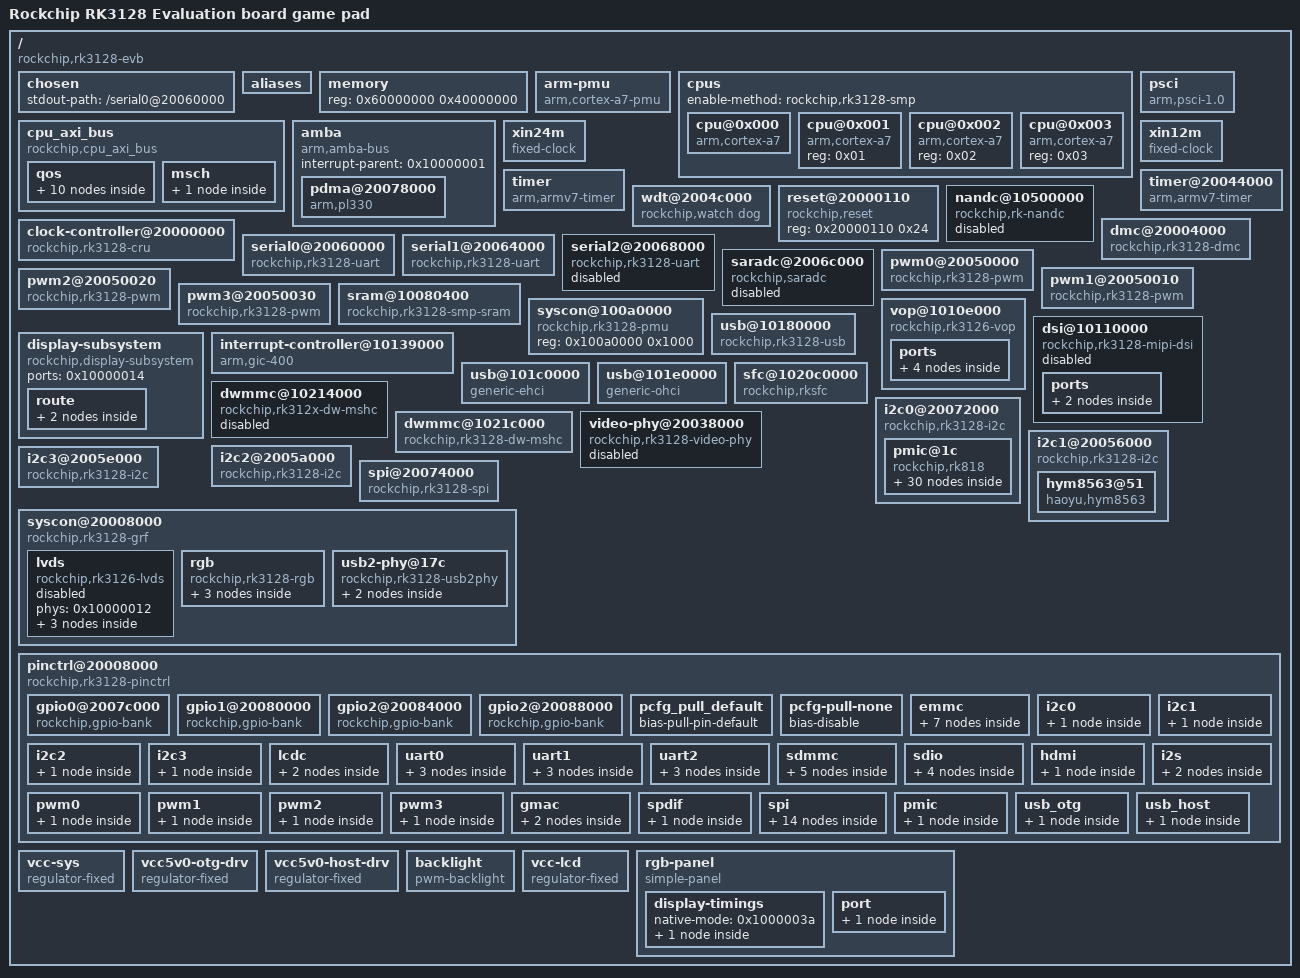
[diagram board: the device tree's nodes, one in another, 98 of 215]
/dts-v1/;

/ {
	#address-cells = <0x01>;
	#size-cells = <0x01>;
	compatible = "rockchip,rk3128-evb\0rockchip,rk3128";
	rockchip,sram = <0x10000000>;
	interrupt-parent = <0x10000001>;
	model = "Rockchip RK3128 Evaluation board game pad";

	chosen {
		stdout-path = "/serial0@20060000";
	};

	aliases {
		gpio0 = "/pinctrl@20008000/gpio0@2007c000";
		gpio1 = "/pinctrl@20008000/gpio1@20080000";
		gpio2 = "/pinctrl@20008000/gpio2@20084000";
		gpio3 = "/pinctrl@20008000/gpio2@20088000";
		i2c0 = "/i2c0@20072000";
		i2c1 = "/i2c1@20056000";
		i2c2 = "/i2c2@2005a000";
		i2c3 = "/i2c3@2005e000";
		spi0 = "/spi@20074000";
		serial0 = "/serial0@20060000";
		serial1 = "/serial1@20064000";
		serial2 = "/serial2@20068000";
		mmc0 = "/dwmmc@1021c000";
		mmc1 = "/dwmmc@10214000";
	};

	memory {
		device_type = "memory";
		reg = <0x60000000 0x40000000>;
	};

	arm-pmu {
		compatible = "arm,cortex-a7-pmu";
		interrupts = <0x00 0x4c 0x04 0x00 0x4d 0x04 0x00 0x4e 0x04 0x00 0x4f 0x04>;
	};

	cpus {
		#address-cells = <0x01>;
		#size-cells = <0x00>;
		enable-method = "rockchip,rk3128-smp";

		cpu@0x000 {
			device_type = "cpu";
			compatible = "arm,cortex-a7";
			reg = <0x00>;
			operating-points = <0xc7380 0xf4240>;
			#cooling-cells = <0x02>;
			clock-latency = <0x9c40>;
			clocks = <0x10000002 0x05>;
		};

		cpu@0x001 {
			device_type = "cpu";
			compatible = "arm,cortex-a7";
			reg = <0x01>;
		};

		cpu@0x002 {
			device_type = "cpu";
			compatible = "arm,cortex-a7";
			reg = <0x02>;
		};

		cpu@0x003 {
			device_type = "cpu";
			compatible = "arm,cortex-a7";
			reg = <0x03>;
		};
	};

	cpu_axi_bus {
		compatible = "rockchip,cpu_axi_bus";
		#address-cells = <0x01>;
		#size-cells = <0x01>;
		ranges;

		qos {
			#address-cells = <0x01>;
			#size-cells = <0x01>;
			ranges;

			crypto {
				reg = <0x10128080 0x20>;
			};

			core {
				reg = <0x1012a000 0x20>;
			};

			peri {
				reg = <0x1012c000 0x20>;
			};

			gpu {
				reg = <0x1012d000 0x20>;
			};

			vpu {
				reg = <0x1012e000 0x20>;
			};

			rga {
				reg = <0x1012f000 0x20>;
			};

			ebc {
				reg = <0x1012f080 0x20>;
			};

			iep {
				reg = <0x1012f100 0x20>;
			};

			lcdc {
				reg = <0x1012f180 0x20>;
				rockchip,priority = <0x03 0x03>;
			};

			vip {
				reg = <0x1012f200 0x20>;
				rockchip,priority = <0x03 0x03>;
			};
		};

		msch {
			#address-cells = <0x01>;
			#size-cells = <0x01>;
			ranges;

			msch@10128000 {
				reg = <0x10128000 0x20>;
				rockchip,read-latency = <0x3f>;
			};
		};
	};

	psci {
		compatible = "arm,psci-1.0";
		method = "smc";
		u-boot,dm-pre-reloc;
		status = "okay";
	};

	amba {
		compatible = "arm,amba-bus";
		#address-cells = <0x01>;
		#size-cells = <0x01>;
		interrupt-parent = <0x10000001>;
		ranges;

		pdma@20078000 {
			compatible = "arm,pl330\0arm,primecell";
			reg = <0x20078000 0x4000>;
			arm,pl330-broken-no-flushp;
			interrupts = <0x00 0x00 0x04 0x00 0x01 0x04>;
			#dma-cells = <0x01>;
			clocks = <0x10000002 0xc2>;
			clock-names = "apb_pclk";
			phandle = <0x10000008>;
		};
	};

	xin24m {
		compatible = "fixed-clock";
		clock-frequency = <0x16e3600>;
		clock-output-names = "xin24m";
		#clock-cells = <0x00>;
		phandle = <0x10000003>;
	};

	xin12m {
		compatible = "fixed-clock";
		clocks = <0x10000003>;
		clock-frequency = <0xb71b00>;
		clock-output-names = "xin12m";
		#clock-cells = <0x00>;
	};

	timer {
		compatible = "arm,armv7-timer";
		arm,cpu-registers-not-fw-configured;
		interrupts = <0x01 0x0d 0xf04 0x01 0x0e 0xf04>;
		clock-frequency = <0x16e3600>;
	};

	timer@20044000 {
		compatible = "arm,armv7-timer";
		reg = <0x20044000 0xb8>;
		interrupts = <0x00 0x1c 0x04>;
		rockchip,broadcast = <0x01>;
	};

	wdt@2004c000 {
		compatible = "rockchip,watch dog";
		reg = <0x2004c000 0x100>;
		clock-names = "pclk_wdt";
		interrupts = <0x00 0x22 0x04>;
		rockchip,irq = <0x01>;
		rockchip,timeout = <0x3c>;
		rockchip,atboot = <0x01>;
		rockchip,debug = <0x00>;
	};

	reset@20000110 {
		compatible = "rockchip,reset";
		reg = <0x20000110 0x24>;
		#reset-cells = <0x01>;
	};

	nandc@10500000 {
		compatible = "rockchip,rk-nandc";
		reg = <0x10500000 0x4000>;
		interrupts = <0x00 0x12 0x04>;
		nandc_id = <0x00>;
		clocks = <0x10000002 0x43 0x10000002 0x1c5>;
		clock-names = "clk_nandc\0hclk_nandc";
		status = "disabled";
	};

	dmc@20004000 {
		compatible = "rockchip,rk3128-dmc\0syscon";
		reg = <0x00 0x20004000 0x00 0x1000>;
		u-boot,dm-pre-reloc;
	};

	clock-controller@20000000 {
		compatible = "rockchip,rk3128-cru";
		reg = <0x20000000 0x1000>;
		rockchip,grf = <0x10000004>;
		#clock-cells = <0x01>;
		#reset-cells = <0x01>;
		assigned-clocks = <0x10000002 0x04>;
		assigned-clock-rates = <0x2367b880>;
		u-boot,dm-pre-reloc;
		phandle = <0x10000002>;
	};

	serial0@20060000 {
		compatible = "rockchip,rk3128-uart\0snps,dw-apb-uart";
		reg = <0x20060000 0x100>;
		interrupts = <0x00 0x14 0x04>;
		reg-shift = <0x02>;
		reg-io-width = <0x04>;
		clock-frequency = <0x16e3600>;
		clocks = <0x10000002 0x4d 0x10000002 0x155>;
		clock-names = "baudclk\0apb_pclk";
		pinctrl-names = "default";
		pinctrl-0 = <0x10000005 0x10000006 0x10000007>;
		dmas = <0x10000008 0x02 0x10000008 0x03>;
		#dma-cells = <0x02>;
		u-boot,dm-pre-reloc;
		status = "okay";
	};

	serial1@20064000 {
		compatible = "rockchip,rk3128-uart\0snps,dw-apb-uart";
		reg = <0x20064000 0x100>;
		interrupts = <0x00 0x15 0x04>;
		reg-shift = <0x02>;
		reg-io-width = <0x04>;
		clock-frequency = <0x16e3600>;
		clocks = <0x10000002 0x4e 0x10000002 0x156>;
		clock-names = "baudclk\0apb_pclk";
		pinctrl-names = "default";
		pinctrl-0 = <0x10000009>;
		dmas = <0x10000008 0x04 0x10000008 0x05>;
		#dma-cells = <0x02>;
	};

	serial2@20068000 {
		compatible = "rockchip,rk3128-uart\0snps,dw-apb-uart";
		reg = <0x20068000 0x100>;
		interrupts = <0x00 0x16 0x04>;
		reg-shift = <0x02>;
		reg-io-width = <0x04>;
		clock-frequency = <0x16e3600>;
		clocks = <0x10000002 0x4f 0x10000002 0x157>;
		clock-names = "baudclk\0apb_pclk";
		pinctrl-names = "default";
		pinctrl-0 = <0x1000000a>;
		dmas = <0x10000008 0x06 0x10000008 0x07>;
		#dma-cells = <0x02>;
		status = "disabled";
	};

	saradc@2006c000 {
		compatible = "rockchip,saradc";
		reg = <0x2006c000 0x100>;
		interrupts = <0x00 0x11 0x04>;
		#io-channel-cells = <0x01>;
		clocks = <0x10000002 0x5b 0x10000002 0x13e>;
		clock-names = "saradc\0apb_pclk";
		resets = <0x10000002 0x57>;
		reset-names = "saradc-apb";
		status = "disabled";
	};

	pwm0@20050000 {
		compatible = "rockchip,rk3128-pwm\0rockchip,rk3288-pwm";
		reg = <0x20050000 0x10>;
		#pwm-cells = <0x03>;
		pinctrl-names = "active";
		pinctrl-0 = <0x1000000b>;
		clocks = <0x10000002 0x15e>;
		clock-names = "pwm";
		phandle = <0x10000036>;
	};

	pwm1@20050010 {
		compatible = "rockchip,rk3128-pwm\0rockchip,rk3288-pwm";
		reg = <0x20050010 0x10>;
		#pwm-cells = <0x02>;
		pinctrl-names = "active";
		pinctrl-0 = <0x1000000c>;
		clocks = <0x10000002 0x15e>;
		clock-names = "pwm";
	};

	pwm2@20050020 {
		compatible = "rockchip,rk3128-pwm\0rockchip,rk3288-pwm";
		reg = <0x20050020 0x10>;
		#pwm-cells = <0x02>;
		pinctrl-names = "active";
		pinctrl-0 = <0x1000000d>;
		clocks = <0x10000002 0x15e>;
		clock-names = "pwm";
	};

	pwm3@20050030 {
		compatible = "rockchip,rk3128-pwm\0rockchip,rk3288-pwm";
		reg = <0x20050030 0x10>;
		#pwm-cells = <0x02>;
		pinctrl-names = "active";
		pinctrl-0 = <0x1000000e>;
		clocks = <0x10000002 0x15e>;
		clock-names = "pwm";
	};

	sram@10080400 {
		compatible = "rockchip,rk3128-smp-sram\0mmio-sram";
		reg = <0x10080400 0x1c00>;
		map-exec;
		map-cacheable;
		phandle = <0x10000000>;
	};

	syscon@100a0000 {
		compatible = "rockchip,rk3128-pmu\0syscon\0simple-mfd";
		reg = <0x100a0000 0x1000>;
		#address-cells = <0x01>;
		#size-cells = <0x01>;
	};

	vop@1010e000 {
		compatible = "rockchip,rk3126-vop";
		reg = <0x1010e000 0x100 0x1010ec00 0x400>;
		reg-names = "regs\0gamma_lut";
		interrupts = <0x00 0x09 0x04>;
		clocks = <0x10000002 0xcc 0x10000002 0xbe 0x10000002 0x1cf>;
		clock-names = "aclk_vop\0dclk_vop\0hclk_vop";
		status = "okay";

		ports {

			port {
				#address-cells = <0x01>;
				#size-cells = <0x00>;
				phandle = <0x10000014>;

				endpoint@0 {
					reg = <0x00>;
					remote-endpoint = <0x1000000f>;
					phandle = <0x10000015>;
				};

				endpoint@1 {
					reg = <0x01>;
					remote-endpoint = <0x10000010>;
					phandle = <0x10000013>;
				};

				endpoint@2 {
					reg = <0x02>;
					remote-endpoint = <0x10000011>;
					phandle = <0x1000002e>;
				};
			};
		};
	};

	dsi@10110000 {
		compatible = "rockchip,rk3128-mipi-dsi";
		reg = <0x10110000 0x4000>;
		interrupts = <0x00 0x21 0x04>;
		clocks = <0x10000002 0x145 0x10000002 0x1d5 0x10000012>;
		clock-names = "pclk\0h2p\0hs_clk";
		resets = <0x10000002 0x89>;
		reset-names = "apb";
		phys = <0x10000012>;
		phy-names = "mipi_dphy";
		rockchip,grf = <0x10000004>;
		#address-cells = <0x01>;
		#size-cells = <0x00>;
		status = "disabled";

		ports {

			port {

				endpoint {
					remote-endpoint = <0x10000013>;
					phandle = <0x10000010>;
				};
			};
		};
	};

	display-subsystem {
		compatible = "rockchip,display-subsystem";
		ports = <0x10000014>;
		status = "okay";

		route {

			route-lvds {
				logo,uboot = "logo.bmp";
				logo,kernel = "logo_kernel.bmp";
				logo,mode = "fullscreen";
				charge_logo,mode = "center";
				connect = <0x10000015>;
				status = "okay";
			};

			route-dsi {
				logo,uboot = "logo.bmp";
				logo,kernel = "logo_kernel.bmp";
				logo,mode = "fullscreen";
				charge_logo,mode = "center";
				connect = <0x10000013>;
				status = "disabled";
			};
		};
	};

	interrupt-controller@10139000 {
		compatible = "arm,gic-400";
		interrupt-controller;
		#interrupt-cells = <0x03>;
		#address-cells = <0x00>;
		reg = <0x10139000 0x1000 0x1013a000 0x1000 0x1013c000 0x2000 0x1013e000 0x2000>;
		interrupts = <0x01 0x09 0xf04>;
		phandle = <0x10000001>;
	};

	usb@10180000 {
		compatible = "rockchip,rk3128-usb\0rockchip,rk3288-usb\0snps,dwc2";
		reg = <0x10180000 0x40000>;
		interrupts = <0x00 0x0a 0x04>;
		dr_mode = "otg";
		g-use-dma;
		hnp-srp-disable;
		phys = <0x10000016>;
		phy-names = "usb";
		status = "okay";
		u-boot,dm-pre-reloc;
		vbus-supply = <0x10000017>;
	};

	usb@101c0000 {
		compatible = "generic-ehci";
		reg = <0x101c0000 0x20000>;
		interrupts = <0x00 0x0b 0x04>;
		phys = <0x10000018>;
		phy-names = "usb";
		status = "okay";
	};

	usb@101e0000 {
		compatible = "generic-ohci";
		reg = <0x101e0000 0x20000>;
		interrupts = <0x00 0x20 0x04>;
		phys = <0x10000018>;
		phy-names = "usb";
		status = "okay";
	};

	sfc@1020c0000 {
		compatible = "rockchip,rksfc";
		reg = <0x1020c000 0x4000>;
		#address-cells = <0x01>;
		#size-cells = <0x00>;
		interrupts = <0x00 0x09 0x04>;
		clocks = <0x10000002 0x99 0x10000002 0x1b7>;
		clock-names = "clk_sfc\0hclk_sfc";
		status = "okay";
		u-boot,dm-pre-reloc;
	};

	dwmmc@10214000 {
		compatible = "rockchip,rk312x-dw-mshc\0rockchip,rk3288-dw-mshc";
		reg = <0x10214000 0x4000>;
		max-frequency = <0x8f0d180>;
		interrupts = <0x00 0x0e 0x04>;
		clocks = <0x10000002 0x1c8 0x10000002 0x44 0x10000002 0x72 0x10000002 0x76>;
		clock-names = "biu\0ciu\0ciu-drv\0ciu-sample";
		fifo-depth = <0x100>;
		pinctrl-names = "default";
		pinctrl-0 = <0x10000019 0x1000001a 0x1000001b>;
		bus-width = <0x04>;
		status = "disabled";
	};

	dwmmc@1021c000 {
		compatible = "rockchip,rk3128-dw-mshc\0rockchip,rk3288-dw-mshc";
		reg = <0x1021c000 0x4000>;
		max-frequency = <0x8f0d180>;
		interrupts = <0x00 0x10 0x04>;
		clocks = <0x10000002 0x1cb 0x10000002 0x47 0x10000002 0x75 0x10000002 0x79>;
		clock-names = "biu\0ciu\0ciu-drv\0ciu-sample";
		bus-width = <0x08>;
		default-sample-phase = <0x9e>;
		num-slots = <0x01>;
		fifo-depth = <0x100>;
		pinctrl-names = "default";
		pinctrl-0 = <0x1000001c 0x1000001d 0x1000001e>;
		resets = <0x10000002 0x53>;
		reset-names = "reset";
		status = "okay";
		fifo-mode;
	};

	video-phy@20038000 {
		compatible = "rockchip,rk3128-video-phy";
		reg = <0x20038000 0x4000 0x10110000 0x4000>;
		clocks = <0x10000002 0x94 0x10000002 0x172 0x10000002 0x145>;
		clock-names = "ref\0pclk_phy\0pclk_host";
		#clock-cells = <0x00>;
		resets = <0x10000002 0x24>;
		reset-names = "rst";
		#phy-cells = <0x00>;
		status = "disabled";
		phandle = <0x10000012>;
	};

	i2c0@20072000 {
		compatible = "rockchip,rk3128-i2c\0rockchip,rk3288-i2c";
		reg = <0x20072000 0x1000>;
		interrupts = <0x00 0x18 0x04>;
		#address-cells = <0x01>;
		#size-cells = <0x00>;
		clock-names = "i2c";
		clocks = <0x10000002 0x14c>;
		pinctrl-names = "default";
		pinctrl-0 = <0x1000001f>;
		status = "okay";
		clock-frequency = <0x61a80>;

		pmic@1c {
			compatible = "rockchip,rk818";
			status = "okay";
			reg = <0x1c>;
			clock-output-names = "rk818-clkout1\0wifibt_32kin";
			interrupt-parent = <0x10000020>;
			interrupts = <0x16 0x08>;
			pinctrl-names = "default";
			pinctrl-0 = <0x10000021>;
			rockchip,system-power-controller;
			wakeup-source;
			#clock-cells = <0x01>;
			vcc1-supply = <0x10000022>;
			vcc2-supply = <0x10000022>;
			vcc3-supply = <0x10000022>;
			vcc4-supply = <0x10000022>;
			vcc6-supply = <0x10000022>;
			vcc7-supply = <0x10000022>;
			vcc8-supply = <0x10000022>;
			vcc9-supply = <0x10000023>;

			regulators {

				DCDC_REG1 {
					regulator-name = "vdd_arm";
					regulator-always-on;
					regulator-boot-on;
					regulator-min-microvolt = <0xb71b0>;
					regulator-max-microvolt = <0x162010>;
					regulator-ramp-delay = <0x1771>;

					regulator-state-mem {
						regulator-on-in-suspend;
						regulator-suspend-microvolt = <0x10c8e0>;
					};
				};

				DCDC_REG2 {
					regulator-name = "vdd_logic";
					regulator-always-on;
					regulator-boot-on;
					regulator-min-microvolt = <0xb71b0>;
					regulator-max-microvolt = <0x162010>;
					regulator-ramp-delay = <0x1771>;

					regulator-state-mem {
						regulator-on-in-suspend;
						regulator-suspend-microvolt = <0x10c8e0>;
					};
				};

				DCDC_REG3 {
					regulator-name = "vcc_ddr";
					regulator-always-on;
					regulator-boot-on;

					regulator-state-mem {
						regulator-on-in-suspend;
					};
				};

				DCDC_REG4 {
					regulator-name = "vcc_io";
					regulator-always-on;
					regulator-boot-on;
					regulator-min-microvolt = <0x325aa0>;
					regulator-max-microvolt = <0x325aa0>;
					phandle = <0x10000023>;

					regulator-state-mem {
						regulator-on-in-suspend;
						regulator-suspend-microvolt = <0x325aa0>;
					};
				};

				LDO_REG1 {
					regulator-name = "rk818_ldo1";
					regulator-always-on;
					regulator-boot-on;
					regulator-min-microvolt = <0x325aa0>;
					regulator-max-microvolt = <0x325aa0>;

					regulator-state-mem {
						regulator-on-in-suspend;
						regulator-suspend-microvolt = <0x325aa0>;
					};
				};

				LDO_REG2 {
					regulator-name = "rk818_ldo2";
					regulator-always-on;
					regulator-boot-on;
					regulator-min-microvolt = <0x2dc6c0>;
					regulator-max-microvolt = <0x2dc6c0>;

					regulator-state-mem {
						regulator-on-in-suspend;
						regulator-suspend-microvolt = <0x2dc6c0>;
					};
				};

				LDO_REG3 {
					regulator-name = "rk818_ldo3";
					regulator-always-on;
					regulator-boot-on;
					regulator-min-microvolt = <0x10c8e0>;
					regulator-max-microvolt = <0x10c8e0>;

					regulator-state-mem {
						regulator-on-in-suspend;
						regulator-suspend-microvolt = <0x10c8e0>;
					};
				};

				LDO_REG4 {
					regulator-name = "rk818_ldo4";
					regulator-always-on;
					regulator-boot-on;
					regulator-min-microvolt = <0x2ab980>;
					regulator-max-microvolt = <0x2ab980>;

					regulator-state-mem {
						regulator-on-in-suspend;
						regulator-suspend-microvolt = <0x2ab980>;
					};
				};

				LDO_REG5 {
					regulator-name = "rk818_ldo5";
					regulator-always-on;
					regulator-boot-on;
					regulator-min-microvolt = <0x2dc6c0>;
					regulator-max-microvolt = <0x2dc6c0>;

					regulator-state-mem {
						regulator-on-in-suspend;
						regulator-suspend-microvolt = <0x2dc6c0>;
					};
				};

				LDO_REG6 {
					regulator-name = "rk818_ldo6";
					regulator-always-on;
					regulator-boot-on;
					regulator-min-microvolt = <0x124f80>;
					regulator-max-microvolt = <0x124f80>;

					regulator-state-mem {
						regulator-on-in-suspend;
						regulator-suspend-microvolt = <0x124f80>;
					};
				};

				LDO_REG7 {
					regulator-name = "rk818_ldo7";
					regulator-always-on;
					regulator-boot-on;
					regulator-min-microvolt = <0x1b7740>;
					regulator-max-microvolt = <0x1b7740>;

					regulator-state-mem {
						regulator-on-in-suspend;
						regulator-suspend-microvolt = <0x1b7740>;
					};
				};

				LDO_REG8 {
					regulator-name = "rk818_ldo8";
					regulator-always-on;
					regulator-boot-on;
					regulator-min-microvolt = <0x1b7740>;
					regulator-max-microvolt = <0x1b7740>;

					regulator-state-mem {
						regulator-on-in-suspend;
						regulator-suspend-microvolt = <0x1b7740>;
					};
				};

				LDO_REG9 {
					regulator-name = "vcc_sd";
					regulator-always-on;
					regulator-boot-on;
					regulator-min-microvolt = <0x1b7740>;
					regulator-max-microvolt = <0x2dc6c0>;

					regulator-state-mem {
						regulator-on-in-suspend;
						regulator-suspend-microvolt = <0x2dc6c0>;
					};
				};

				SWITCH_REG {
					regulator-name = "rk818_ldo10";
					regulator-always-on;
					regulator-boot-on;

					regulator-state-mem {
						regulator-on-in-suspend;
					};
				};
			};

			battery {
				compatible = "rk818-battery";
				ocv_table = <0xd48 0xe42 0xe6d 0xe7b 0xe93 0xea5 0xeb0 0xeba 0xec6 0xed4 0xee4 0xef5 0xf0c 0xf2a 0xf4b 0xf6f 0xf8d 0xfcf 0xff6 0x1024 0x1056>;
				design_capacity = <0xfa0>;
				design_qmax = <0xfa0>;
				bat_res = <0x64>;
				max_input_current = <0x7d0>;
				max_chrg_current = <0x578>;
				max_chrg_voltage = <0x1068>;
				sleep_enter_current = <0x12c>;
				sleep_exit_current = <0x12c>;
				power_off_thresd = <0xd48>;
				zero_algorithm_vol = <0xf0a>;
				energy_mode = <0x00>;
				fb_temperature = <0x69>;
				sample_res = <0x14>;
				max_soc_offset = <0x3c>;
				monitor_sec = <0x05>;
				virtual_power = <0x01>;
				power_dc2otg = <0x00>;
			};
		};
	};

	i2c1@20056000 {
		compatible = "rockchip,rk3128-i2c\0rockchip,rk3288-i2c";
		reg = <0x20056000 0x1000>;
		interrupts = <0x00 0x19 0x04>;
		#address-cells = <0x01>;
		#size-cells = <0x00>;
		clock-names = "i2c";
		clocks = <0x10000002 0x14d>;
		pinctrl-names = "default";
		pinctrl-0 = <0x10000024>;
		status = "okay";

		hym8563@51 {
			compatible = "haoyu,hym8563";
			reg = <0x51>;
			#clock-cells = <0x00>;
			clock-frequency = <0x8000>;
			clock-output-names = "xin32k";
		};
	};

	i2c2@2005a000 {
		compatible = "rockchip,rk3128-i2c\0rockchip,rk3288-i2c";
		reg = <0x2005a000 0x1000>;
		interrupts = <0x00 0x1a 0x04>;
		#address-cells = <0x01>;
		#size-cells = <0x00>;
		clock-names = "i2c";
		clocks = <0x10000002 0x14e>;
		pinctrl-names = "default";
		pinctrl-0 = <0x10000025>;
	};

	i2c3@2005e000 {
		compatible = "rockchip,rk3128-i2c\0rockchip,rk3288-i2c";
		reg = <0x2005e000 0x1000>;
		interrupts = <0x00 0x1b 0x04>;
		#address-cells = <0x01>;
		#size-cells = <0x00>;
		clock-names = "i2c";
		clocks = <0x10000002 0x14f>;
		pinctrl-names = "default";
		pinctrl-0 = <0x10000026>;
	};

	spi@20074000 {
		compatible = "rockchip,rk3128-spi\0rockchip,rk3288-spi";
		reg = <0x20074000 0x1000>;
		interrupts = <0x00 0x17 0x04>;
		pinctrl-names = "default";
		pinctrl-0 = <0x10000027 0x10000028 0x10000029 0x1000002a 0x1000002b>;
		clock-names = "spiclk\0apb_pclk";
		clocks = <0x10000002 0x152 0x10000002 0x152>;
		dmas = <0x10000008 0x08 0x10000008 0x09>;
		dma-names = "tx\0rx";
		#address-cells = <0x01>;
		#size-cells = <0x00>;
		status = "okay";
	};

	syscon@20008000 {
		compatible = "rockchip,rk3128-grf\0syscon";
		reg = <0x20008000 0x1000>;
		u-boot,dm-pre-reloc;
		phandle = <0x10000004>;

		lvds {
			compatible = "rockchip,rk3126-lvds";
			phys = <0x10000012>;
			phy-names = "phy";
			status = "disabled";

			ports {
				#address-cells = <0x01>;
				#size-cells = <0x00>;

				port@0 {
					reg = <0x00>;

					endpoint {
						remote-endpoint = <0x10000015>;
						phandle = <0x1000000f>;
					};
				};
			};
		};

		rgb {
			compatible = "rockchip,rk3128-rgb";
			phys = <0x10000012>;
			phy-names = "phy";
			pinctrl-names = "default\0sleep";
			pinctrl-0 = <0x1000002c>;
			pinctrl-1 = <0x1000002d>;
			status = "okay";

			ports {
				#address-cells = <0x01>;
				#size-cells = <0x00>;

				port@0 {
					reg = <0x00>;

					endpoint {
						remote-endpoint = <0x1000002e>;
						phandle = <0x10000011>;
					};
				};
			};
		};

		usb2-phy@17c {
			compatible = "rockchip,rk3128-usb2phy";
			reg = <0x17c 0x0c>;
			clocks = <0x10000002 0x8e>;
			clock-names = "phyclk";
			#clock-cells = <0x00>;
			clock-output-names = "usb480m_phy";
			assigned-clocks = <0x10000002 0x9a>;
			assigned-clock-parents = <0x1000002f>;
			status = "okay";
			u-boot,dm-pre-reloc;
			phandle = <0x1000002f>;

			otg-port {
				#phy-cells = <0x00>;
				interrupts = <0x00 0x23 0x04 0x00 0x33 0x04 0x00 0x34 0x04>;
				interrupt-names = "otg-bvalid\0otg-id\0linestate";
				status = "okay";
				u-boot,dm-pre-reloc;
				phandle = <0x10000016>;
			};

			host-port {
				#phy-cells = <0x00>;
				interrupts = <0x00 0x35 0x04>;
				interrupt-names = "linestate";
				status = "okay";
				phandle = <0x10000018>;
			};
		};
	};

	pinctrl@20008000 {
		compatible = "rockchip,rk3128-pinctrl";
		reg = <0x20008000 0xa8 0x200080a8 0x4c 0x20008118 0x20 0x20008100 0x04>;
		reg-names = "base\0mux\0pull\0drv";
		rockchip,grf = <0x10000004>;
		#address-cells = <0x01>;
		#size-cells = <0x01>;
		ranges;

		gpio0@2007c000 {
			compatible = "rockchip,gpio-bank";
			reg = <0x2007c000 0x100>;
			interrupts = <0x00 0x24 0x04>;
			clocks = <0x10000002 0x140>;
			gpio-controller;
			#gpio-cells = <0x02>;
			interrupt-controller;
			#interrupt-cells = <0x02>;
			phandle = <0x10000032>;
		};

		gpio1@20080000 {
			compatible = "rockchip,gpio-bank";
			reg = <0x20080000 0x100>;
			interrupts = <0x00 0x25 0x04>;
			clocks = <0x10000002 0x141>;
			gpio-controller;
			#gpio-cells = <0x02>;
			interrupt-controller;
			#interrupt-cells = <0x02>;
			phandle = <0x10000037>;
		};

		gpio2@20084000 {
			compatible = "rockchip,gpio-bank";
			reg = <0x20084000 0x100>;
			interrupts = <0x00 0x26 0x04>;
			clocks = <0x10000002 0x142>;
			gpio-controller;
			#gpio-cells = <0x02>;
			interrupt-controller;
			#interrupt-cells = <0x02>;
			phandle = <0x10000034>;
		};

		gpio2@20088000 {
			compatible = "rockchip,gpio-bank";
			reg = <0x20088000 0x100>;
			interrupts = <0x00 0x27 0x04>;
			clocks = <0x10000002 0x143>;
			gpio-controller;
			#gpio-cells = <0x02>;
			interrupt-controller;
			#interrupt-cells = <0x02>;
			phandle = <0x10000020>;
		};

		pcfg_pull_default {
			bias-pull-pin-default;
			phandle = <0x10000031>;
		};

		pcfg-pull-none {
			bias-disable;
			phandle = <0x10000030>;
		};

		emmc {

			emmc-clk {
				rockchip,pins = <0x02 0x07 0x02 0x10000030>;
				phandle = <0x1000001c>;
			};

			emmc-cmd {
				rockchip,pins = <0x01 0x16 0x02 0x10000031>;
				phandle = <0x1000001d>;
			};

			emmc-cmd1 {
				rockchip,pins = <0x02 0x04 0x02 0x10000031>;
			};

			emmc-pwr {
				rockchip,pins = <0x02 0x05 0x02 0x10000031>;
			};

			emmc-bus1 {
				rockchip,pins = <0x01 0x18 0x02 0x10000031>;
			};

			emmc-bus4 {
				rockchip,pins = <0x01 0x18 0x02 0x10000031 0x01 0x19 0x02 0x10000031 0x01 0x1a 0x02 0x10000031 0x01 0x1b 0x02 0x10000031>;
			};

			emmc-bus8 {
				rockchip,pins = <0x01 0x18 0x02 0x10000031 0x01 0x19 0x02 0x10000031 0x01 0x1a 0x02 0x10000031 0x01 0x1b 0x02 0x10000031 0x01 0x1c 0x02 0x10000031 0x01 0x1d 0x02 0x10000031 0x01 0x1e 0x02 0x10000031 0x01 0x1f 0x02 0x10000031>;
				phandle = <0x1000001e>;
			};
		};

		i2c0 {

			i2c0-xfer {
				rockchip,pins = <0x00 0x00 0x01 0x10000030 0x00 0x01 0x01 0x10000030>;
				phandle = <0x1000001f>;
			};
		};

		i2c1 {

			i2c1-xfer {
				rockchip,pins = <0x00 0x02 0x01 0x10000030 0x00 0x03 0x01 0x10000030>;
				phandle = <0x10000024>;
			};
		};

		i2c2 {

			i2c2-xfer {
				rockchip,pins = <0x02 0x14 0x03 0x10000030 0x02 0x15 0x03 0x10000030>;
				phandle = <0x10000025>;
			};
		};

		i2c3 {

			i2c3-xfer {
				rockchip,pins = <0x00 0x06 0x01 0x10000030 0x00 0x07 0x01 0x10000030>;
				phandle = <0x10000026>;
			};
		};

		lcdc {

			lcdc-rgb-pins {
				rockchip,pins = <0x02 0x08 0x01 0x10000030 0x02 0x09 0x01 0x10000030 0x02 0x0a 0x01 0x10000030 0x02 0x0b 0x01 0x10000030 0x02 0x0c 0x01 0x10000030 0x02 0x0d 0x01 0x10000030 0x02 0x0e 0x01 0x10000030 0x02 0x0f 0x01 0x10000030 0x02 0x10 0x01 0x10000030 0x02 0x11 0x01 0x10000030 0x02 0x12 0x01 0x10000030 0x02 0x13 0x01 0x10000030 0x02 0x14 0x01 0x10000030 0x02 0x15 0x01 0x10000030 0x02 0x16 0x01 0x10000030 0x02 0x17 0x01 0x10000030 0x02 0x18 0x01 0x10000030 0x02 0x19 0x01 0x10000030>;
				phandle = <0x1000002c>;
			};

			lcdc-sleep-pins {
				rockchip,pins = <0x02 0x08 0x00 0x10000030 0x02 0x09 0x00 0x10000030 0x02 0x0a 0x00 0x10000030 0x02 0x0b 0x00 0x10000030 0x02 0x0c 0x00 0x10000030 0x02 0x0d 0x00 0x10000030 0x02 0x0e 0x00 0x10000030 0x02 0x0f 0x00 0x10000030 0x02 0x10 0x00 0x10000030 0x02 0x11 0x00 0x10000030 0x02 0x12 0x00 0x10000030 0x02 0x13 0x00 0x10000030 0x02 0x14 0x00 0x10000030 0x02 0x15 0x00 0x10000030 0x02 0x16 0x00 0x10000030 0x02 0x17 0x00 0x10000030 0x02 0x18 0x00 0x10000030 0x02 0x19 0x00 0x10000030>;
				phandle = <0x1000002d>;
			};
		};

		uart0 {

			uart0-xfer {
				rockchip,pins = <0x02 0x1a 0x02 0x10000031 0x02 0x1b 0x02 0x10000030>;
				phandle = <0x10000005>;
			};

			uart0-cts {
				rockchip,pins = <0x02 0x1d 0x02 0x10000030>;
				phandle = <0x10000006>;
			};

			uart0-rts {
				rockchip,pins = <0x00 0x11 0x02 0x10000030>;
				phandle = <0x10000007>;
			};
		};

		uart1 {

			uart1-xfer {
				rockchip,pins = <0x01 0x09 0x02 0x10000031 0x01 0x0a 0x02 0x10000031>;
				phandle = <0x10000009>;
			};

			uart1-cts {
				rockchip,pins = <0x01 0x08 0x02 0x10000030>;
			};

			uart1-rts {
				rockchip,pins = <0x01 0x0b 0x02 0x10000030>;
			};
		};

		uart2 {

			uart2-xfer {
				rockchip,pins = <0x01 0x12 0x02 0x10000031 0x01 0x13 0x02 0x10000030>;
				phandle = <0x1000000a>;
			};

			uart2-cts {
				rockchip,pins = <0x00 0x19 0x01 0x10000030>;
			};

			uart2-rts {
				rockchip,pins = <0x00 0x18 0x01 0x10000030>;
			};
		};

		sdmmc {

			sdmmc-clk {
				rockchip,pins = <0x01 0x10 0x01 0x10000030>;
				phandle = <0x10000019>;
			};

			sdmmc-cmd {
				rockchip,pins = <0x01 0x0f 0x01 0x10000031>;
				phandle = <0x1000001a>;
			};

			sdmmc-wp {
				rockchip,pins = <0x01 0x07 0x01 0x10000031>;
			};

			sdmmc-pwren {
				rockchip,pins = <0x01 0x0e 0x01 0x10000031>;
			};

			sdmmc-bus4 {
				rockchip,pins = <0x01 0x12 0x01 0x10000031 0x01 0x13 0x01 0x10000031 0x01 0x14 0x01 0x10000031 0x01 0x15 0x01 0x10000031>;
				phandle = <0x1000001b>;
			};
		};

		sdio {

			sdio-clk {
				rockchip,pins = <0x01 0x00 0x02 0x10000030>;
			};

			sdio-cmd {
				rockchip,pins = <0x00 0x03 0x02 0x10000031>;
			};

			sdio-pwren {
				rockchip,pins = <0x00 0x1e 0x01 0x10000031>;
			};

			sdio-bus4 {
				rockchip,pins = <0x01 0x01 0x02 0x10000031 0x01 0x02 0x02 0x10000031 0x01 0x04 0x02 0x10000031 0x01 0x05 0x02 0x10000031>;
			};
		};

		hdmi {

			hdmii2c-xfer {
				rockchip,pins = <0x00 0x06 0x02 0x10000030 0x00 0x07 0x02 0x10000030>;
			};
		};

		i2s {

			i2s-bus {
				rockchip,pins = <0x00 0x08 0x01 0x10000030 0x00 0x09 0x01 0x10000030 0x00 0x0b 0x01 0x10000030 0x00 0x0c 0x01 0x10000030 0x00 0x0d 0x01 0x10000030 0x00 0x0e 0x01 0x10000030>;
			};

			i2s1-bus {
				rockchip,pins = <0x01 0x00 0x01 0x10000030 0x01 0x01 0x01 0x10000030 0x01 0x02 0x01 0x10000030 0x01 0x03 0x01 0x10000030 0x01 0x04 0x01 0x10000030 0x01 0x05 0x01 0x10000030>;
			};
		};

		pwm0 {

			pwm0-pin {
				rockchip,pins = <0x00 0x1a 0x01 0x10000030>;
				phandle = <0x1000000b>;
			};
		};

		pwm1 {

			pwm1-pin {
				rockchip,pins = <0x00 0x1b 0x01 0x10000030>;
				phandle = <0x1000000c>;
			};
		};

		pwm2 {

			pwm2-pin {
				rockchip,pins = <0x00 0x1c 0x01 0x10000030>;
				phandle = <0x1000000d>;
			};
		};

		pwm3 {

			pwm3-pin {
				rockchip,pins = <0x03 0x1a 0x01 0x10000030>;
				phandle = <0x1000000e>;
			};
		};

		gmac {

			rgmii-pins {
				rockchip,pins = <0x02 0x08 0x03 0x10000031 0x02 0x09 0x03 0x10000031 0x02 0x0b 0x03 0x10000031 0x02 0x0c 0x03 0x10000031 0x02 0x0d 0x03 0x10000031 0x02 0x0e 0x03 0x10000031 0x02 0x10 0x03 0x10000031 0x02 0x11 0x03 0x10000031 0x02 0x12 0x03 0x10000031 0x02 0x13 0x03 0x10000031 0x02 0x19 0x03 0x10000031 0x02 0x14 0x04 0x10000031 0x02 0x15 0x04 0x10000031 0x02 0x16 0x04 0x10000031 0x02 0x17 0x04 0x10000031>;
			};

			rmii-pins {
				rockchip,pins = <0x02 0x08 0x03 0x10000031 0x02 0x0c 0x03 0x10000031 0x02 0x0d 0x03 0x10000031 0x02 0x0e 0x03 0x10000031 0x02 0x0f 0x03 0x10000031 0x02 0x10 0x03 0x10000031 0x02 0x11 0x03 0x10000031 0x02 0x13 0x03 0x10000031 0x02 0x14 0x03 0x10000031 0x02 0x19 0x03 0x10000031>;
			};
		};

		spdif {

			spdif-tx {
				rockchip,pins = <0x03 0x1b 0x01 0x10000030>;
			};
		};

		spi {

			spi0-clk {
				rockchip,pins = <0x01 0x08 0x01 0x10000031>;
				phandle = <0x10000029>;
			};

			spi0-cs0 {
				rockchip,pins = <0x01 0x0b 0x01 0x10000031>;
				phandle = <0x1000002a>;
			};

			spi0-tx {
				rockchip,pins = <0x01 0x09 0x01 0x10000031>;
				phandle = <0x10000027>;
			};

			spi0-rx {
				rockchip,pins = <0x01 0x0a 0x01 0x10000031>;
				phandle = <0x10000028>;
			};

			spi0-cs1 {
				rockchip,pins = <0x01 0x0c 0x01 0x10000031>;
				phandle = <0x1000002b>;
			};

			spi1-clk {
				rockchip,pins = <0x02 0x00 0x02 0x10000031>;
			};

			spi1-cs0 {
				rockchip,pins = <0x01 0x1e 0x03 0x10000031>;
			};

			spi1-tx {
				rockchip,pins = <0x01 0x1d 0x03 0x10000031>;
			};

			spi1-rx {
				rockchip,pins = <0x01 0x1c 0x03 0x10000031>;
			};

			spi1-cs1 {
				rockchip,pins = <0x01 0x1f 0x03 0x10000031>;
			};

			spi2-clk {
				rockchip,pins = <0x00 0x09 0x02 0x10000031>;
			};

			spi2-cs0 {
				rockchip,pins = <0x00 0x0e 0x02 0x10000031>;
			};

			spi2-tx {
				rockchip,pins = <0x00 0x0b 0x02 0x10000031>;
			};

			spi2-rx {
				rockchip,pins = <0x00 0x0d 0x02 0x10000031>;
			};
		};

		pmic {

			pmic-int-l {
				rockchip,pins = <0x03 0x16 0x00 0x10000031>;
				phandle = <0x10000021>;
			};
		};

		usb_otg {

			otg-vbus-drv {
				rockchip,pins = <0x00 0x1a 0x00 0x10000030>;
				phandle = <0x10000033>;
			};
		};

		usb_host {

			host-vbus-drv {
				rockchip,pins = <0x02 0x17 0x00 0x10000030>;
				phandle = <0x10000035>;
			};
		};
	};

	vcc-sys {
		compatible = "regulator-fixed";
		regulator-name = "vcc_sys";
		regulator-always-on;
		regulator-boot-on;
		regulator-min-microvolt = <0x4c4b40>;
		regulator-max-microvolt = <0x4c4b40>;
		phandle = <0x10000022>;
	};

	vcc5v0-otg-drv {
		compatible = "regulator-fixed";
		regulator-name = "vcc5v0_otg";
		gpio = <0x10000032 0x1a 0x00>;
		pinctrl-names = "default";
		pinctrl-0 = <0x10000033>;
		regulator-min-microvolt = <0x4c4b40>;
		regulator-max-microvolt = <0x4c4b40>;
		phandle = <0x10000017>;
	};

	vcc5v0-host-drv {
		compatible = "regulator-fixed";
		regulator-name = "vcc5v0_host";
		gpio = <0x10000034 0x17 0x00>;
		pinctrl-names = "default";
		pinctrl-0 = <0x10000035>;
		regulator-min-microvolt = <0x4c4b40>;
		regulator-max-microvolt = <0x4c4b40>;
		regulator-always-on;
	};

	backlight {
		compatible = "pwm-backlight";
		brightness-levels = <0x00 0x01 0x02 0x03 0x04 0x05 0x06 0x07 0x08 0x09 0x0a 0x0b 0x0c 0x0d 0x0e 0x0f 0x10 0x11 0x12 0x13 0x14 0x15 0x16 0x17 0x18 0x19 0x1a 0x1b 0x1c 0x1d 0x1e 0x1f 0x20 0x21 0x22 0x23 0x24 0x25 0x26 0x27 0x28 0x29 0x2a 0x2b 0x2c 0x2d 0x2e 0x2f 0x30 0x31 0x32 0x33 0x34 0x35 0x36 0x37 0x38 0x39 0x3a 0x3b 0x3c 0x3d 0x3e 0x3f 0x40 0x41 0x42 0x43 0x44 0x45 0x46 0x47 0x48 0x49 0x4a 0x4b 0x4c 0x4d 0x4e 0x4f 0x50 0x51 0x52 0x53 0x54 0x55 0x56 0x57 0x58 0x59 0x5a 0x5b 0x5c 0x5d 0x5e 0x5f 0x60 0x61 0x62 0x63 0x64 0x65 0x66 0x67 0x68 0x69 0x6a 0x6b 0x6c 0x6d 0x6e 0x6f 0x70 0x71 0x72 0x73 0x74 0x75 0x76 0x77 0x78 0x79 0x7a 0x7b 0x7c 0x7d 0x7e 0x7f 0x80 0x81 0x82 0x83 0x84 0x85 0x86 0x87 0x88 0x89 0x8a 0x8b 0x8c 0x8d 0x8e 0x8f 0x90 0x91 0x92 0x93 0x94 0x95 0x96 0x97 0x98 0x99 0x9a 0x9b 0x9c 0x9d 0x9e 0x9f 0xa0 0xa1 0xa2 0xa3 0xa4 0xa5 0xa6 0xa7 0xa8 0xa9 0xaa 0xab 0xac 0xad 0xae 0xaf 0xb0 0xb1 0xb2 0xb3 0xb4 0xb5 0xb6 0xb7 0xb8 0xb9 0xba 0xbb 0xbc 0xbd 0xbe 0xbf 0xc0 0xc1 0xc2 0xc3 0xc4 0xc5 0xc6 0xc7 0xc8 0xc9 0xca 0xcb 0xcc 0xcd 0xce 0xcf 0xd0 0xd1 0xd2 0xd3 0xd4 0xd5 0xd6 0xd7 0xd8 0xd9 0xda 0xdb 0xdc 0xdd 0xde 0xdf 0xe0 0xe1 0xe2 0xe3 0xe4 0xe5 0xe6 0xe7 0xe8 0xe9 0xea 0xeb 0xec 0xed 0xee 0xef 0xf0 0xf1 0xf2 0xf3 0xf4 0xf5 0xf6 0xf7 0xf8 0xf9 0xfa 0xfb 0xfc 0xfd 0xfe 0xff>;
		default-brightness-level = <0xff>;
		pwms = <0x10000036 0x00 0x61a8 0x00>;
		status = "okay";
		phandle = <0x10000039>;
	};

	vcc-lcd {
		compatible = "regulator-fixed";
		gpio = <0x10000037 0x0c 0x01>;
		regulator-name = "vcc_lcd";
		regulator-min-microvolt = <0x325aa0>;
		regulator-max-microvolt = <0x325aa0>;
		vin-supply = <0x10000023>;
		phandle = <0x10000038>;
	};

	rgb-panel {
		compatible = "simple-panel";
		power-supply = <0x10000038>;
		backlight = <0x10000039>;
		enable-gpios = <0x10000032 0x18 0x00>;
		prepare-delay-ms = <0x64>;
		enable-delay-ms = <0x82>;
		bus-format = <0x1009>;
		width-mm = <0x69>;
		height-mm = <0x43>;
		reset-gpios = <0x10000032 0x18 0x01>;
		reset-delay-ms = <0x3c>;
		rockchip,data-width = <0x12>;
		rockchip,output = "rgb";

		display-timings {
			native-mode = <0x1000003a>;

			timing0 {
				clock-frequency = <0x30d4000>;
				hactive = <0x400>;
				hback-porch = <0xa0>;
				hfront-porch = <0xa0>;
				hsync-len = <0x0a>;
				vactive = <0x258>;
				vback-porch = <0x17>;
				vfront-porch = <0x0c>;
				vsync-len = <0x0a>;
				hsync-active = <0x00>;
				vsync-active = <0x00>;
				de-active = <0x00>;
				pixelclk-active = <0x01>;
				phandle = <0x1000003a>;
			};
		};

		port {

			endpoint {
				remote-endpoint = <0x10000015>;
			};
		};
	};
};
